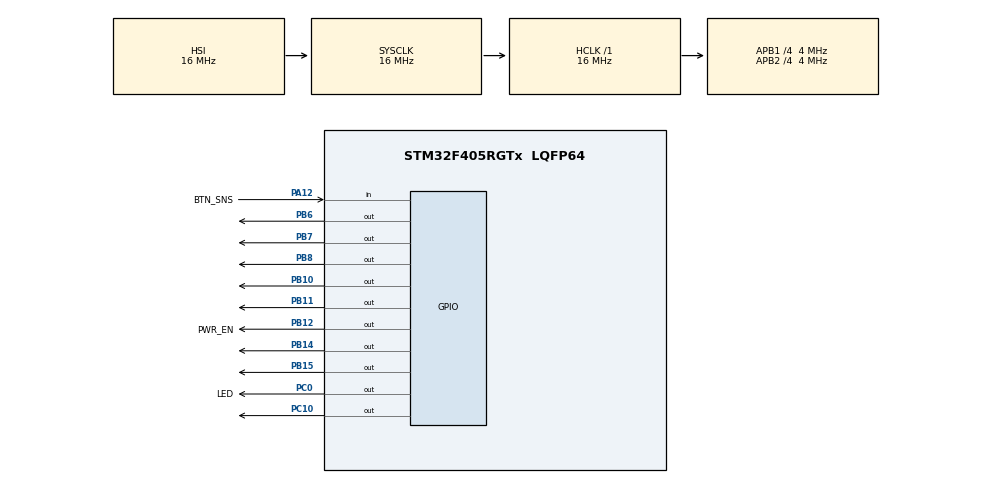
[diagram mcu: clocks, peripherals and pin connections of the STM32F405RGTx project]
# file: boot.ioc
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Mcu.Family=STM32F4
Mcu.Name=STM32F405RGTx
Mcu.Package=LQFP64
NVIC.PriorityGroup=NVIC_PRIORITYGROUP_4
PA12.GPIO_Label=BTN_SNS
PA12.Signal=GPIO_Input
PA13.Mode=Serial_Wire
PA13.Signal=SYS_JTMS-SWDIO
PA14.Mode=Serial_Wire
PA14.Signal=SYS_JTCK-SWCLK
PB10.Signal=GPIO_Output
PB11.Signal=GPIO_Output
PB12.GPIO_Label=PWR_EN
PB12.PinState=GPIO_PIN_SET
PB12.Signal=GPIO_Output
PB14.Signal=GPIO_Output
PB15.Signal=GPIO_Output
PB6.Signal=GPIO_Output
PB7.Signal=GPIO_Output
PB8.Signal=GPIO_Output
PC0.GPIO_Label=LED
PC0.Signal=GPIO_Output
PC10.Signal=GPIO_Output
ProjectManager.HeapSize=0x200
ProjectManager.StackSize=0x400
ProjectManager.TargetToolchain=Makefile
RCC.48MHZClocksFreq_Value=48000000
RCC.AHBFreq_Value=16000000
RCC.APB1CLKDivider=RCC_HCLK_DIV4
RCC.APB1Freq_Value=4000000
RCC.APB1TimFreq_Value=8000000
RCC.APB2CLKDivider=RCC_HCLK_DIV4
RCC.APB2Freq_Value=4000000
RCC.APB2TimFreq_Value=8000000
RCC.CortexFreq_Value=16000000
RCC.HCLKFreq_Value=16000000
RCC.HSE_VALUE=25000000
RCC.HSI_VALUE=16000000
RCC.LSE_VALUE=32768
RCC.PLLM=8
RCC.PLLN=96
RCC.SYSCLKFreq_VALUE=16000000
RCC.VCOOutputFreq_Value=192000000
VP_CRC_VS_CRC.Mode=CRC_Activate
board=custom

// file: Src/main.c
/* USER CODE BEGIN Header */
/**
  ******************************************************************************
  * @file           : main.c
  * @brief          : Main program body
  ******************************************************************************
  * @attention
  *
  * <h2><center>&copy; Copyright (c) 2019 STMicroelectronics.
  * All rights reserved.</center></h2>
  *
  * This software component is licensed by ST under BSD 3-Clause license,
  * the "License"; You may not use this file except in compliance with the
  * License. You may obtain a copy of the License at:
  *                        opensource.org/licenses/BSD-3-Clause
  *
  ******************************************************************************
  */
/* USER CODE END Header */

#include "main.h"

/* USER CODE BEGIN PD */
void loop(void);
/* USER CODE END PD */

CRC_HandleTypeDef hcrc;

void SystemClock_Config(void);
static void MX_GPIO_Init(void);
static void MX_CRC_Init(void);
/* USER CODE BEGIN PFP */
void init(void);
/* USER CODE END PFP */

int main(void)
{

  /* MCU Configuration--------------------------------------------------------*/

  /* Reset of all peripherals, Initializes the Flash interface and the Systick. */
  HAL_Init();

  /* Configure the system clock */
  SystemClock_Config();

  /* Initialize all configured peripherals */
  MX_GPIO_Init();
  MX_CRC_Init();
  /* USER CODE BEGIN 2 */
  init();
  /* USER CODE END 2 */

  /* Infinite loop */
  /* USER CODE BEGIN WHILE */
  while (1)
  {
      loop();
    /* USER CODE END WHILE */

  }
}

void SystemClock_Config(void)
{
  RCC_OscInitTypeDef RCC_OscInitStruct = {0};
  RCC_ClkInitTypeDef RCC_ClkInitStruct = {0};

  /** Configure the main internal regulator output voltage
  */
  __HAL_RCC_PWR_CLK_ENABLE();
  __HAL_PWR_VOLTAGESCALING_CONFIG(PWR_REGULATOR_VOLTAGE_SCALE1);
  /** Initializes the CPU, AHB and APB busses clocks
  */
  RCC_OscInitStruct.OscillatorType = RCC_OSCILLATORTYPE_HSI;
  RCC_OscInitStruct.HSIState = RCC_HSI_ON;
  RCC_OscInitStruct.HSICalibrationValue = RCC_HSICALIBRATION_DEFAULT;
  RCC_OscInitStruct.PLL.PLLState = RCC_PLL_NONE;
  if (HAL_RCC_OscConfig(&RCC_OscInitStruct) != HAL_OK)
  {
    Error_Handler();
  }
  /** Initializes the CPU, AHB and APB busses clocks
  */
  RCC_ClkInitStruct.ClockType = RCC_CLOCKTYPE_HCLK|RCC_CLOCKTYPE_SYSCLK
                              |RCC_CLOCKTYPE_PCLK1|RCC_CLOCKTYPE_PCLK2;
  RCC_ClkInitStruct.SYSCLKSource = RCC_SYSCLKSOURCE_HSI;
  RCC_ClkInitStruct.AHBCLKDivider = RCC_SYSCLK_DIV1;
  RCC_ClkInitStruct.APB1CLKDivider = RCC_HCLK_DIV4;
  RCC_ClkInitStruct.APB2CLKDivider = RCC_HCLK_DIV4;

  if (HAL_RCC_ClockConfig(&RCC_ClkInitStruct, FLASH_LATENCY_0) != HAL_OK)
  {
    Error_Handler();
  }
}

static void MX_CRC_Init(void)
{

  hcrc.Instance = CRC;
  if (HAL_CRC_Init(&hcrc) != HAL_OK)
  {
    Error_Handler();
  }

}

static void MX_GPIO_Init(void)
{
  GPIO_InitTypeDef GPIO_InitStruct = {0};

  /* GPIO Ports Clock Enable */
  __HAL_RCC_GPIOC_CLK_ENABLE();
  __HAL_RCC_GPIOB_CLK_ENABLE();
  __HAL_RCC_GPIOA_CLK_ENABLE();

  /*Configure GPIO pin Output Level */
  HAL_GPIO_WritePin(GPIOC, LED_Pin|GPIO_PIN_10, GPIO_PIN_RESET);

  /*Configure GPIO pin Output Level */
  HAL_GPIO_WritePin(GPIOB, GPIO_PIN_10|GPIO_PIN_11|GPIO_PIN_14|GPIO_PIN_15
                          |GPIO_PIN_6|GPIO_PIN_7|GPIO_PIN_8, GPIO_PIN_RESET);

  /*Configure GPIO pin Output Level */
  HAL_GPIO_WritePin(PWR_EN_GPIO_Port, PWR_EN_Pin, GPIO_PIN_SET);

  /*Configure GPIO pins : LED_Pin PC10 */
  GPIO_InitStruct.Pin = LED_Pin|GPIO_PIN_10;
  GPIO_InitStruct.Mode = GPIO_MODE_OUTPUT_PP;
  GPIO_InitStruct.Pull = GPIO_NOPULL;
  GPIO_InitStruct.Speed = GPIO_SPEED_FREQ_LOW;
  HAL_GPIO_Init(GPIOC, &GPIO_InitStruct);

  /*Configure GPIO pins : PB10 PB11 PWR_EN_Pin PB14
                           PB15 PB6 PB7 PB8 */
  GPIO_InitStruct.Pin = GPIO_PIN_10|GPIO_PIN_11|PWR_EN_Pin|GPIO_PIN_14
                          |GPIO_PIN_15|GPIO_PIN_6|GPIO_PIN_7|GPIO_PIN_8;
  GPIO_InitStruct.Mode = GPIO_MODE_OUTPUT_PP;
  GPIO_InitStruct.Pull = GPIO_NOPULL;
  GPIO_InitStruct.Speed = GPIO_SPEED_FREQ_LOW;
  HAL_GPIO_Init(GPIOB, &GPIO_InitStruct);

  /*Configure GPIO pin : BTN_SNS_Pin */
  GPIO_InitStruct.Pin = BTN_SNS_Pin;
  GPIO_InitStruct.Mode = GPIO_MODE_INPUT;
  GPIO_InitStruct.Pull = GPIO_NOPULL;
  HAL_GPIO_Init(BTN_SNS_GPIO_Port, &GPIO_InitStruct);

}

void Error_Handler(void)
{
}

/************************ (C) COPYRIGHT STMicroelectronics *****END OF FILE****/
